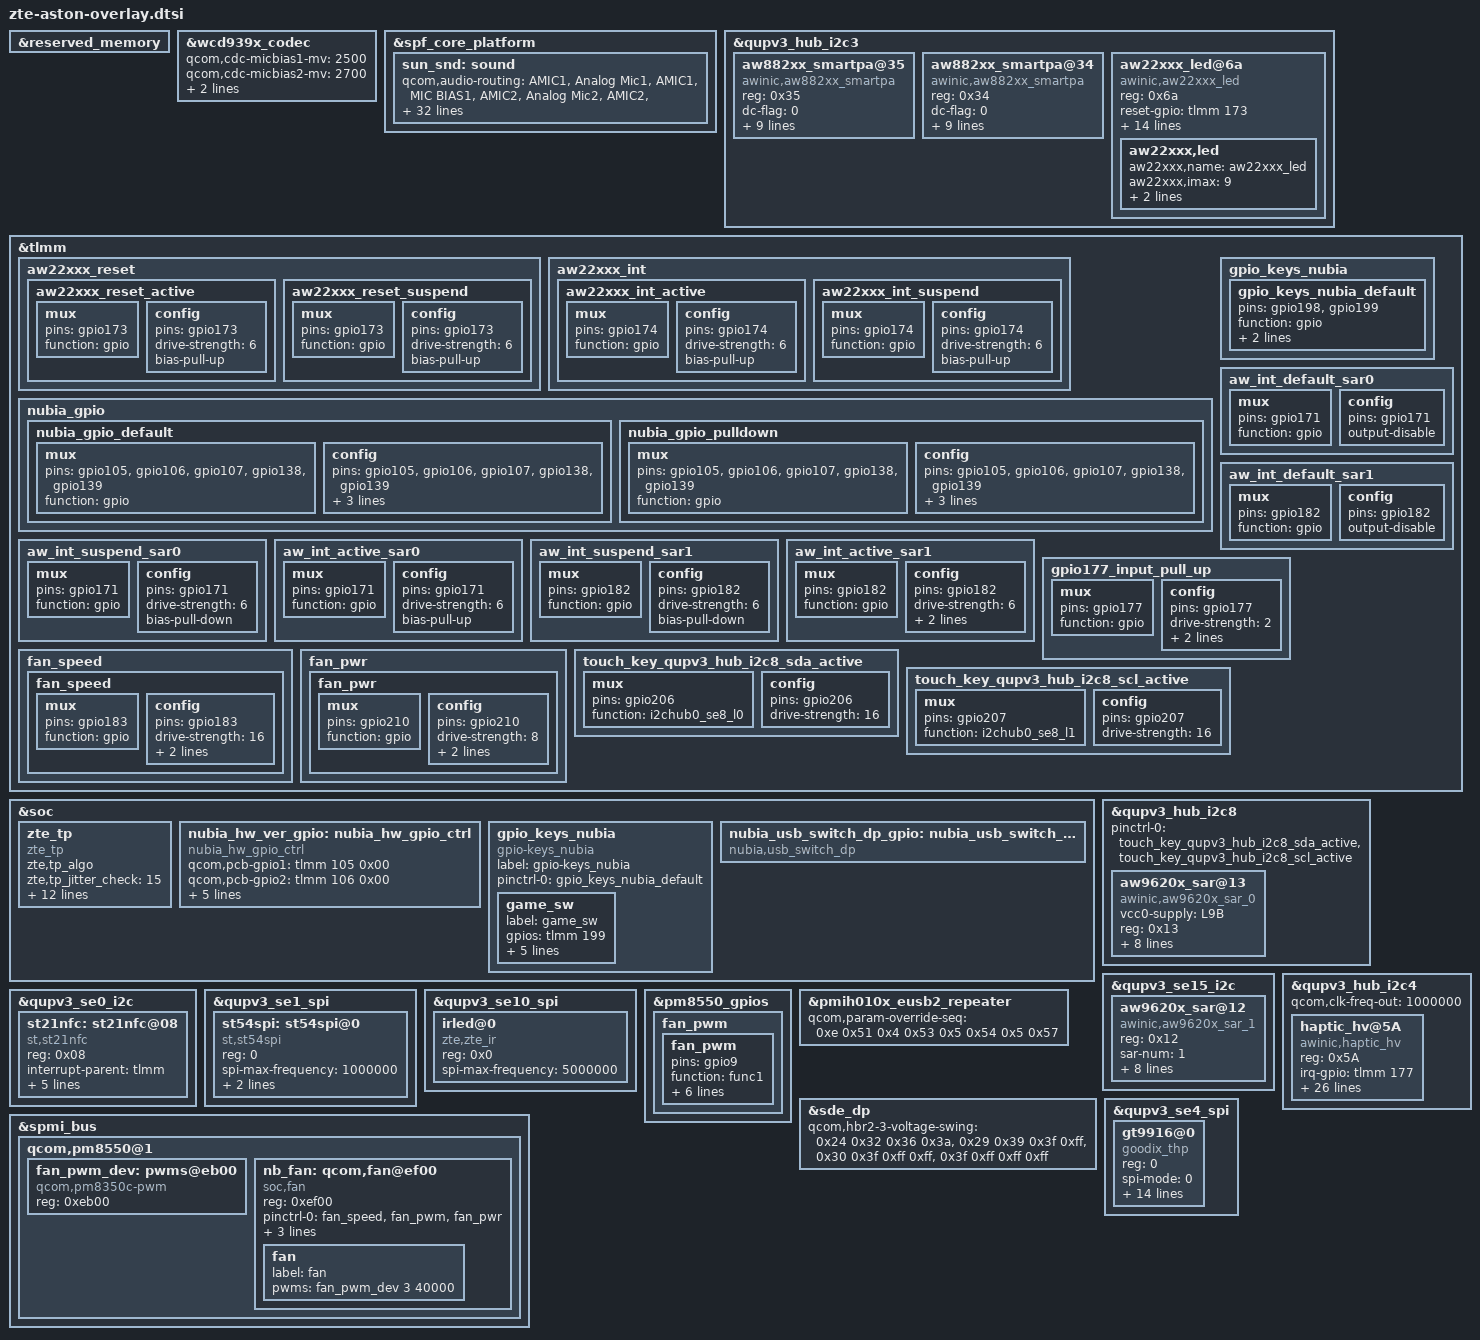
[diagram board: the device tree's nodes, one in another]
/* dtsi for aston board (NX789J)*/
#include <dt-bindings/gpio/gpio.h>
#include <dt-bindings/input/input.h>
#include "../zte-fingerprint-sun-goodix.dtsi"
#include <dt-bindings/clock/qcom,rpmh.h>
#include <dt-bindings/gpio/gpio.h>
#include <dt-bindings/input/input.h>

&reserved_memory {
};

&wcd939x_codec {
        qcom,cdc-micbias1-mv = <2500>;
        qcom,cdc-micbias2-mv = <2700>;
        qcom,cdc-micbias3-mv = <2500>;
        qcom,cdc-micbias4-mv = <2500>;
};

&spf_core_platform  {
	sun_snd: sound {
		qcom,audio-routing =
			"AMIC1", "Analog Mic1",
			"AMIC1", "MIC BIAS1",
			"AMIC2", "Analog Mic2",
			"AMIC2", "MIC BIAS2",
			"AMIC3", "Analog Mic3",
			"AMIC3", "MIC BIAS3",
			"AMIC4", "Analog Mic4",
			"AMIC4", "MIC BIAS4",
			"AMIC5", "Analog Mic5",
			"AMIC5", "MIC BIAS4",
			"VA AMIC1", "Analog Mic1",
			"VA AMIC1", "VA MIC BIAS1",
			"VA AMIC2", "Analog Mic2",
			"VA AMIC2", "VA MIC BIAS2",
			"VA AMIC3", "Analog Mic3",
			"VA AMIC3", "VA MIC BIAS3",
			"VA AMIC4", "Analog Mic4",
			"VA AMIC4", "VA MIC BIAS3",
			"VA AMIC5", "Analog Mic5",
			"VA AMIC5", "VA MIC BIAS4",
			"TX DMIC0", "Digital Mic0",
			"TX DMIC0", "MIC BIAS1",
			"TX DMIC1", "Digital Mic1",
			"TX DMIC1", "MIC BIAS3",
			"TX DMIC2", "Digital Mic2",
			"TX DMIC2", "MIC BIAS3",
			"TX DMIC3", "Digital Mic3",
			"TX DMIC3", "MIC BIAS1",
			"IN1_HPHL", "HPHL_OUT",
			"IN2_HPHR", "HPHR_OUT",
			"IN3_EAR", "AUX_OUT",
			"RX_TX DEC0_INP", "TX DEC0 MUX",
			"RX_TX DEC1_INP", "TX DEC1 MUX",
			"RX_TX DEC2_INP", "TX DEC2 MUX",
			"RX_TX DEC3_INP", "TX DEC3 MUX",
			"TX SWR_INPUT", "WCD_TX_OUTPUT",
			"VA SWR_INPUT", "VA_SWR_CLK",
			"VA SWR_INPUT", "WCD_TX_OUTPUT",
			"VA_AIF1 CAP", "VA_SWR_CLK",
			"VA_AIF2 CAP", "VA_SWR_CLK",
			"VA_AIF3 CAP", "VA_SWR_CLK",
			"VA DMIC0", "Digital Mic0",
			"VA DMIC1", "Digital Mic1",
			"VA DMIC2", "Digital Mic2",
			"VA DMIC3", "Digital Mic3",
			"VA DMIC0", "VA MIC BIAS1",
			"VA DMIC1", "VA MIC BIAS3",
			"VA DMIC2", "VA MIC BIAS3",
			"VA DMIC3", "VA MIC BIAS1";
		qcom,msm-mbhc-usbc-audio-supported = <0>;
		qcom,msm-mbhc-hphl-swh = <1>;
		qcom,msm-mbhc-gnd-swh = <1>;
                /* Fix MBHC looseness leads to identification as Line-out */
                qcom,msm-mbhc-hs-mic-max-threshold-mv = <2700>;
        };
};

&qupv3_hub_i2c3 {
        status = "okay";
        /* AWINIC AW882XX Smart PA */
        aw882xx_smartpa@35 {
                compatible = "awinic,aw882xx_smartpa";
                reg = <0x35>;
                dc-flag = <0>;
                sync-flag = <0>;
                sound-channel = <0>;
                aw-tx-topo-id = <0x1000ff00>;
                aw-rx-topo-id = <0x1000ff01>;
                aw-tx-port-id = <0x1007>;
                aw-rx-port-id = <0x1006>;
                aw-re-min = <4000>;
                aw-re-max= <30000>;
                /*aw-cali-mode = "none";*/
                monitor-mode = "hal_monitor";
        };
        aw882xx_smartpa@34 {
                compatible = "awinic,aw882xx_smartpa";
                reg = <0x34>;
                dc-flag = <0>;
                sync-flag = <0>;
                sound-channel = <1>;
                aw-tx-topo-id = <0x1000ff00>;
                aw-rx-topo-id = <0x1000ff01>;
                aw-tx-port-id = <0x1007>;
                aw-rx-port-id = <0x1006>;
                aw-re-min = <4000>;
                aw-re-max= <30000>;
                /*aw-cali-mode = "none";*/
                monitor-mode = "hal_monitor";
        };

	/*aw22xxx_led*/
	
	aw22xxx_led@6a {
	status = "okay";
		compatible = "awinic,aw22xxx_led";
		reg = <0x6a>;
		reset-gpio = <&tlmm 173 0x0>;
		nubia_ver-gpio = <&tlmm 7 1>;
		interrupt-parent = <&tlmm>;
		interrupts = <174 0x2002>;
		irq-gpio = <&tlmm 174 0x2002>;
		qcom,clk-freq-out = <400000>;
		pinctrl-names = "aw22xxx_led_default", "aw22xxx_led_sleep";
		pinctrl-0 = <&aw22xxx_int_active &aw22xxx_reset_active>;
		pinctrl-1 = <&aw22xxx_int_suspend &aw22xxx_reset_suspend>;
		cfg_custom_en = <1>;
		/*aw22xxx_cfg_name[0:13] en flag */
		cfg_base_en = <1 1 1 1 0 0 0 0 1 1 1 1 1 1 1>;
		/*steady lighting up,breath,flashing,flow,ripple,echo,hopping,fast flashing,follows the audio,two flashing*/
		cfg_modex_count = <14 14 14 7 7 7 7 14 15 7>;
		touch_modex_count = <14 14 14 7 7 7 7 14 15 7>;
		fan_modex_count = <16 16 16 16 16>;
		aw22xxx,led {
			aw22xxx,name = "aw22xxx_led";
			aw22xxx,imax = <9>;
			aw22xxx,brightness = <128>;
			aw22xxx,max_brightness = <255>;
		};
	};
};

/*aw22xxx_led*/
&tlmm{
	aw22xxx_reset {
		aw22xxx_reset_active: aw22xxx_reset_active {
			mux {
				pins = "gpio173";
				function = "gpio";
			};
			config {
				pins = "gpio173";
				drive-strength = <6>;
				bias-pull-up;
			};
		};

		aw22xxx_reset_suspend: aw22xxx_reset_suspend {
			mux {
				pins = "gpio173";
				function = "gpio";
			};
			config {
				pins = "gpio173";
				drive-strength = <6>;
				bias-pull-up;
			};
		};
	};

	aw22xxx_int {
		aw22xxx_int_active: aw22xxx_int_active {
			mux {
				pins = "gpio174";
				function = "gpio";
			};
			config {
				pins = "gpio174";
				drive-strength = <6>;
				bias-pull-up;
			};
		};
		aw22xxx_int_suspend: aw22xxx_int_suspend {
			mux {
				pins = "gpio174";
				function = "gpio";
			};
			config {
				pins = "gpio174";
				drive-strength = <6>;
				bias-pull-up;
			};
		};
	};
};

&soc {
	zte_tp:zte_tp {
		compatible = "zte_tp";
		zte,tp_algo;
		zte,tp_jitter_check = <15>;
		zte,tp_jitter_timer = <80>;
		zte,tp_long_press;
		zte,tp_long_press_timer = <800>;
		zte,tp_long_press_left_v = <20>;
		zte,tp_long_press_right_v = <20>;
		zte,tp_long_press_left_h = <20>; /*camera */
		zte,tp_long_press_right_h = <20>; /*charger */
		zte,tp_edge_click_suppression_pixel = <32>;
		zte,ufp_enable;
		zte,ufp_circle_center_x = <9728>;
		zte,ufp_circle_center_y = <32384>;
		zte,ufp_circle_radius = <1920>;
	};

	nubia_hw_ver_gpio: nubia_hw_gpio_ctrl {
		compatible = "nubia_hw_gpio_ctrl";
		qcom,pcb-gpio1 = <&tlmm 105 0x00>;
		qcom,pcb-gpio2 = <&tlmm 106 0x00>;
		qcom,pcb-gpio3 = <&tlmm 107 0x00>;
		qcom,rf-gpio1 = <&tlmm 138 0x00>;
		qcom,rf-gpio2 = <&tlmm 139 0x00>;
		pinctrl-names = "pull_up_default","pull_down_default";
		pinctrl-0 = <&nubia_gpio_default>;
		pinctrl-1 = <&nubia_gpio_pulldown>;
	};

	gpio_keys_nubia {
		status = "ok";
		compatible = "gpio-keys_nubia";
		label = "gpio-keys_nubia";
		pinctrl-names ="default";
		pinctrl-0 = <&gpio_keys_nubia_default>;
		game_sw {
			label = "game_sw";
			gpios = <&tlmm 199 0>;
			gpion = <&tlmm 198 0>;
			linux,input-type = <5>;
			linux,code = <0x0f>;
			debounce-interval = <30>;
			gpio-key,wakeup;
		};
	};

    nubia_usb_switch_dp_gpio: nubia_usb_switch_dp_gpio_ctrl {
        compatible = "nubia,usb_switch_dp";
        status = "okay";
    };
};

&tlmm{
	nubia_gpio {
		nubia_gpio_default: nubia_gpio_default {
			mux {
				pins = "gpio105", "gpio106", "gpio107", "gpio138", "gpio139";
				function = "gpio";
			};
			config {
				pins = "gpio105", "gpio106", "gpio107", "gpio138", "gpio139";
				driver-strength = <2>; /* 2mA */
				bias-pull-up;
				input-enable;
			};
		};

		nubia_gpio_pulldown: nubia_gpio_pulldown {
			mux {
				pins = "gpio105", "gpio106", "gpio107", "gpio138", "gpio139";
				function = "gpio";
			};
			config {
				pins = "gpio105", "gpio106", "gpio107", "gpio138", "gpio139";
				driver-strength = <2>; /* 2mA */
				bias-pull-down;
				input-enable;
			};
		};
	};

	gpio_keys_nubia {
		gpio_keys_nubia_default: gpio_keys_nubia_default {
			pins = "gpio198", "gpio199";
			function = "gpio";
			input-enable;
			bias-disable;
		};
	};

	aw_int_default_sar0: aw_int_default_sar0 {
			mux {
				pins = "gpio171";
				function = "gpio";
			};
			config {
				pins = "gpio171";
				output-disable;
			};
		};
	aw_int_suspend_sar0: aw_int_suspend_sar0 {
		mux {
				pins = "gpio171";
				function = "gpio";
			};
		config {
				pins = "gpio171";
				drive-strength = <6>;
				bias-pull-down;
		   };
		};
	aw_int_active_sar0: aw_int_active_sar0 {
		mux {
				pins = "gpio171";
				function = "gpio";
			};
		config {
				pins = "gpio171";
				drive-strength = <6>;
				bias-pull-up;
			};
		};
	aw_int_default_sar1: aw_int_default_sar1 {
		mux {
				pins = "gpio182";
				function = "gpio";
		};
		config{
				pins = "gpio182";
				output-disable;
		};
	};
	aw_int_suspend_sar1: aw_int_suspend_sar1 {
		mux {
				pins = "gpio182";
				function = "gpio";
	};
		config{
				pins = "gpio182";
				drive-strength = <6>;
				bias-pull-down;
		};
	};
	aw_int_active_sar1: aw_int_active_sar1 {
		mux {
				pins = "gpio182";
				function = "gpio";
		};
		config {
				pins = "gpio182";
				drive-strength = <6>;
				bias-pull-up;
				qcom,i2c_pull = <0>;
		};
	};
};

&qupv3_hub_i2c8 {
		status = "ok";
		aw9620x_sar@13 {
			compatible = "awinic,aw9620x_sar_0";
			vcc0-supply = <&L9B>;
			reg = <0x13>;
			sar-num = < 0 >;
			interrupt-parent = < &tlmm >;
			interrupts = <171 0>;
			irq-gpio = <&tlmm 171 0>;
			pinctrl-names = "aw_int_default_sar0", "aw_int_active_sar0", "aw_int_suspend_sar0";
			pinctrl-0 = <&aw_int_default_sar0>;
			pinctrl-1 = <&aw_int_active_sar0>;
			pinctrl-2 = <&aw_int_suspend_sar0>;
			channel_use_flag = <0x01>;
			status = "okay";
		};
};

&qupv3_se15_i2c {
		status = "ok";
		aw9620x_sar@12 {
			compatible = "awinic,aw9620x_sar_1";
			reg = < 0x12 >;
			sar-num = < 1 >;
			interrupt-parent = < &tlmm >;
			interrupts = <182 0>;
			irq-gpio = <&tlmm 182 0>;
			pinctrl-names = "aw_int_default_sar1", "aw_int_active_sar1", "aw_int_suspend_sar1";
			pinctrl-0 = <&aw_int_default_sar1>;
			pinctrl-1 = <&aw_int_active_sar1>;
			pinctrl-2 = <&aw_int_suspend_sar1>;
			vcc1-supply = <&L9B>;
			channel_use_flag = <0x01>;
			status = "okay";
		};

};

/* add zte haptic start */
&qupv3_hub_i2c4 {
	status = "ok";
	qcom,clk-freq-out = <1000000>;
	haptic_hv@5A {
		compatible = "awinic,haptic_hv";
		reg = <0x5A>;
		irq-gpio = <&tlmm 177 0>;
		reset-gpio = <&tlmm 178 0>;
		pinctrl-names = "irq_active";
		pinctrl-0 = <&gpio177_input_pull_up>;
		f0_pre = < 1700 >;
		mode = /bits/ 8 < 5 >;
		f0_cali_percent = /bits/ 8 < 7 >;
/******************************aw8692x*******************************/
		aw8692x_max_bst_vol = /bits/ 8 < 0x7F >;
		aw8692x_cont_drv1_lvl = /bits/ 8 < 0x7F >;
		aw8692x_cont_drv2_lvl = /bits/ 8 < 0x26 >; /* 0.9Vrms */
		aw8692x_cont_drv1_time = /bits/ 8 < 0x04 >;
		aw8692x_cont_drv2_time = /bits/ 8 < 0x14 >; /* 10 period */
		aw8692x_cont_drv_width = /bits/ 8 < 0x71 >;
		aw8692x_cont_wait_num = /bits/ 8 < 0x06 >;
		aw8692x_cont_brk_time = /bits/ 8 < 0 >;
		aw8692x_cont_track_margin = /bits/ 8 < 0x0C >;
		aw8692x_brk_bst_md = /bits/ 8 < 0 >;
		aw8692x_cont_tset = /bits/ 8 < 0x06 >;
		aw8692x_cont_bemf_set = /bits/ 8 < 0x02 >;
		aw8692x_cont_bst_brk_gain = /bits/ 8 < 0x05 >;
		aw8692x_cont_brk_gain = /bits/ 8 < 0x08 >;
		aw8692x_duration_time = /bits/ 8 < 20 30 60 >;
		aw8692x_d2s_gain = /bits/ 8 < 0x04 >;
		aw8692x_trig_config = /bits/ 8 < 0 0 0 1 0 2 0 0
						 0 0 0 1 0 2 0 0
						 0 0 0 1 0 2 0 0 >;
		aw8692x_bst_vol_default = /bits/ 8 < 0x48 >; /* 8.0Vrms */
		aw8692x_bst_vol_ram = /bits/ 8 < 0x48 >;
		aw8692x_bst_vol_rtp = /bits/ 8 < 0x48 >;
		/* aw8692x_is_enabled_auto_bst; */
		/* aw8692x_is_enabled_one_wire; */
	};
};

&tlmm {
	gpio177_input_pull_up: gpio177_input_pull_up {
		mux {
			 pins = "gpio177";
			 function = "gpio";
		};

		config {
			pins = "gpio177";
			drive-strength = <2>;
			bias-pull-up;
			input-enable;
		};
	};
};

&qupv3_se0_i2c {
	status = "ok";
	/delete-node/ nq@28;
	st21nfc: st21nfc@08 {
		compatible = "st,st21nfc";
		reg = <0x08>;
		interrupt-parent = <&tlmm>;
		interrupts = <75  0>;
		reset-gpios = <&tlmm 34 0x00>;
		irq-gpios = <&tlmm 75 0x00>;
		//boost-gpios = <&tlmm 90 0x00>;
		//pidle-gpios = <&tlmm 48 0x00>;
		clkreq-gpios = <&tlmm 35 0x00>;
		//clocks = <&clock_rpmh RPMH_RF_CLK3>;
		//clock-names = "nfc_ref_clk";
		st,clk_pinctrl;
		status = "ok";
	};
};

&qupv3_se1_spi {
	status = "ok";
	st54spi: st54spi@0 {
		compatible = "st,st54spi";
		reg = <0>;
		spi-max-frequency = <1000000>;
		/* gpio used as SE_PWR_REQ or SE_nRESET */
		gpio-power_nreset-std = <&tlmm 46 0x00>;

		/* Power management mode: none, ST54H (default), ST54J */
		power_mode = "ST54J";
		status = "ok";
	};
};

&qupv3_se10_spi {
	status = "ok";
	irled@0 {
		status = "ok";
		compatible = "zte,zte_ir";
		reg = <0x0>;
		spi-max-frequency = <5000000>;
	};
};

/*fan start*/
&tlmm {
    fan_speed{
        fan_speed: fan_speed {
			mux {
				pins = "gpio183";
				function = "gpio";
			};
			config {
				pins = "gpio183";
				drive-strength = <16>;
                                bias-pull-up;
				input-enable;
			};

        };

    };
	fan_pwr{
        fan_pwr: fan_pwr {
			mux {
				pins = "gpio210";
				function = "gpio";
			};
			config {
				pins = "gpio210";
				drive-strength = <8>;
                                bias-disable;
				output-high;
			};
        };

    };
};

&pm8550_gpios {
    fan_pwm {
        fan_pwm: fan_pwm {
			pins = "gpio9";
			function = "func1";
			input-disable;
			output-enable;
			output-high;
			//bias-disable;
			qcom,drive-strength = <3>;
			power-source = <0>;     /* 1.8V */
			drive-push-pull;
	    };
    };
};

&spmi_bus {
    qcom,pm8550@1 {
       fan_pwm_dev: pwms@eb00 {
            compatible = "qcom,pm8350c-pwm";
            reg = <0xeb00>;
            #address-cells = <1>;
            #size-cells = <0>;
            #pwm-cells = <2>;
        };

        nb_fan: qcom,fan@ef00 {
            compatible = "soc,fan";
            reg = <0xef00>;
            pinctrl-names ="default";
            pinctrl-0 =<&fan_speed &fan_pwm &fan_pwr>;
            fan,pwm-gpio = <&pm8550_gpios 9 GPIO_ACTIVE_HIGH>;
            fan,speed-gpio = <&tlmm 183 GPIO_ACTIVE_HIGH>;
            fan,en-gpio = <&tlmm 210 GPIO_ACTIVE_HIGH>;
            fan {
                label = "fan";
                pwms = <&fan_pwm_dev 3 40000>;
            };
         };
    };
};
/*fan end*/

/* begin usb2.0 eye diagram */
&pmih010x_eusb2_repeater {
	qcom,param-override-seq =
		/* <value reg_offset> */
		/* Adjust HS trasmit amplitude */
		<0xe 0x51
		/* HS Disconnect Threshold */
		 0x4 0x53
		/* Squelch Detector Threshold */
		 0x5 0x54
		/* Tx pre-emphasis tuning */
		 0x5 0x57>;
};
/* end usb2.0 eye diagram */

/* begin DP eye diagram */
&sde_dp {
	qcom,hbr2-3-voltage-swing = <0x24 0x32 0x36 0x3a>,
				<0x29 0x39 0x3f 0xff>,
				<0x30 0x3f 0xff 0xff>,
				<0x3f 0xff 0xff 0xff>;
};
/* end DP eye diagram */

&qupv3_se4_spi {
	status = "ok";

	gt9916@0 {
		compatible = "goodix_thp";
		reg = <0>;
		spi-mode = <0>;
		bits-per-word = <8>;
		spi-max-frequency = <20000000>;
		goodix,avdd-name = "avdd";
		avdd-supply = <&L14B>;
		goodix,iovdd-name = "vdd";
		vdd-supply = <&L4B>;
		chip-type = <2>; // 1: gt9897 2: gt9916 3: gt9966 4: gt9615
		goodix,reset-gpio = <&tlmm 161 0x0>;
		goodix,irq-gpio = <&tlmm 162 0x2>;
		goodix,irq-flags = <2>; /* 1:trigger rising, 2:trigger falling;*/
		goodix,panel-max-x = <19456>;
		goodix,panel-max-y = <43008>;
		goodix,panel-max-w = <4080>;
		panel = <&dsi_bf237_rm692h5_6p8_dev0_dsc_cmd>;
	};
};

/* Started by AICoder, pid:tdde4d13c6k014a14dda0bba301bac1c28c9b557 */
//TOUCH_KEY: gpio206/207 changed to external pull-up
&tlmm {
	touch_key_qupv3_hub_i2c8_sda_active: touch_key_qupv3_hub_i2c8_sda_active {
		mux {
			pins = "gpio206";
			function = "i2chub0_se8_l0";
		};

		config {
			pins = "gpio206";
			drive-strength = <16>;
		};
	};

	touch_key_qupv3_hub_i2c8_scl_active: touch_key_qupv3_hub_i2c8_scl_active {
		mux {
			pins = "gpio207";
			function = "i2chub0_se8_l1";
		};

		config {
			pins = "gpio207";
			drive-strength = <16>;
		};
	};
};

&qupv3_hub_i2c8 {
	status = "ok";
	pinctrl-names = "default", "sleep";
	pinctrl-0 = <&touch_key_qupv3_hub_i2c8_sda_active>, <&touch_key_qupv3_hub_i2c8_scl_active>;
};
/* Ended by AICoder, pid:tdde4d13c6k014a14dda0bba301bac1c28c9b557 */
